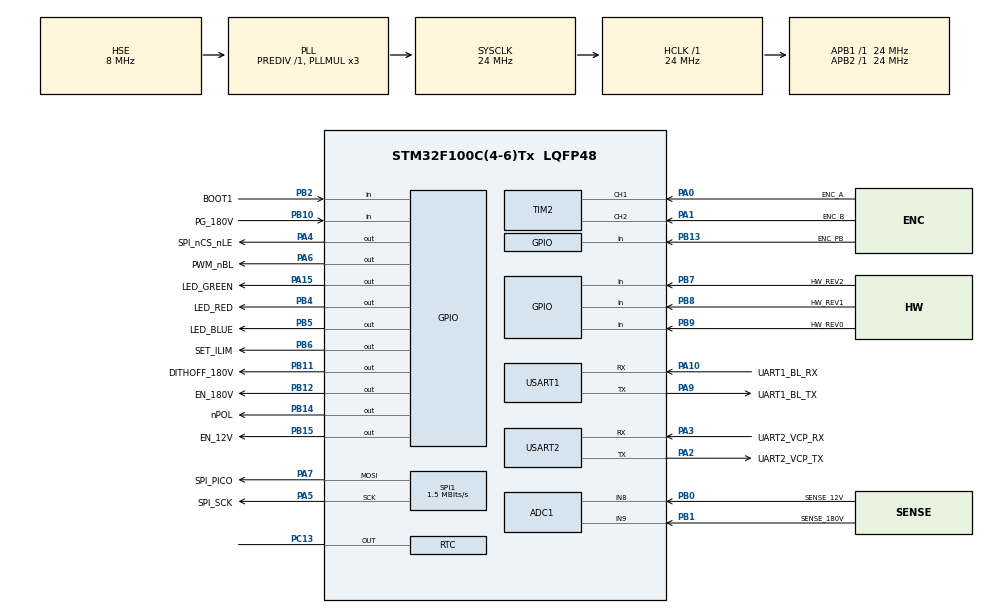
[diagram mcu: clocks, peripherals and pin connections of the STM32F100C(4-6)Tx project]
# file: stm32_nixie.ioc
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ADC1.Channel-4\#ChannelRegularConversion=ADC_CHANNEL_9
ADC1.NbrOfConversionFlag=1
ADC1.Rank-4\#ChannelRegularConversion=1
ADC1.SamplingTime-4\#ChannelRegularConversion=ADC_SAMPLETIME_1CYCLE_5
ADC1.master=1
Mcu.Family=STM32F1
Mcu.Name=STM32F100C(4-6)Tx
Mcu.Package=LQFP48
NVIC.PriorityGroup=NVIC_PRIORITYGROUP_4
NVIC.TIM2_IRQn=true\:0\:0\:false\:false\:true\:true\:true\:true
PA0-WKUP.GPIO_Label=ENC_A
PA0-WKUP.Signal=S_TIM2_CH1_ETR
PA1.GPIO_Label=ENC_B
PA1.Signal=S_TIM2_CH2
PA10.GPIO_Label=UART1_BL_RX
PA10.Mode=Asynchronous
PA10.Signal=USART1_RX
PA13.Mode=Serial_Wire
PA13.Signal=SYS_JTMS-SWDIO
PA14.Mode=Serial_Wire
PA14.Signal=SYS_JTCK-SWCLK
PA15.GPIO_Label=LED_GREEN
PA15.Signal=GPIO_Output
PA2.GPIO_Label=UART2_VCP_TX
PA2.Mode=Asynchronous
PA2.Signal=USART2_TX
PA3.GPIO_Label=UART2_VCP_RX
PA3.Mode=Asynchronous
PA3.Signal=USART2_RX
PA4.GPIO_Label=SPI_nCS_nLE
PA4.Signal=GPIO_Output
PA5.GPIO_Label=SPI_SCK
PA5.Mode=TX_Only_Simplex_Unidirect_Master
PA5.Signal=SPI1_SCK
PA6.GPIO_Label=PWM_nBL
PA6.Signal=GPIO_Output
PA7.GPIO_Label=SPI_PICO
PA7.Mode=TX_Only_Simplex_Unidirect_Master
PA7.Signal=SPI1_MOSI
PA9.GPIO_Label=UART1_BL_TX
PA9.Mode=Asynchronous
PA9.Signal=USART1_TX
PB0.GPIO_Label=SENSE_12V
PB0.Signal=ADCx_IN8
PB1.GPIO_Label=SENSE_180V
PB1.Signal=ADCx_IN9
PB10.GPIO_Label=PG_180V
PB10.Signal=GPIO_Input
PB11.GPIO_Label=DITHOFF_180V
PB11.Signal=GPIO_Output
PB12.GPIO_Label=EN_180V
PB12.Signal=GPIO_Output
PB13.GPIO_Label=ENC_PB
PB13.Signal=GPIO_Input
PB14.GPIO_Label=nPOL
PB14.Signal=GPIO_Output
PB15.GPIO_Label=EN_12V
PB15.Signal=GPIO_Output
PB2.GPIO_Label=BOOT1
PB2.Signal=GPIO_Input
PB3.Signal=SYS_JTDO-TRACESWO
PB4.GPIO_Label=LED_RED
PB4.Signal=GPIO_Output
PB5.GPIO_Label=LED_BLUE
PB5.Signal=GPIO_Output
PB6.GPIO_Label=SET_ILIM
PB6.Signal=GPIO_Output
PB7.GPIO_Label=HW_REV2
PB7.GPIO_PuPd=GPIO_PULLUP
PB7.Signal=GPIO_Input
PB8.GPIO_Label=HW_REV1
PB8.GPIO_PuPd=GPIO_PULLUP
PB8.Signal=GPIO_Input
PB9.GPIO_Label=HW_REV0
PB9.GPIO_PuPd=GPIO_PULLUP
PB9.Signal=GPIO_Input
PC13-TAMPER-RTC.Mode=RTC OUT
PC13-TAMPER-RTC.Signal=RTC_OUT
PC14-OSC32_IN.Mode=LSE-External-Oscillator
PC14-OSC32_IN.Signal=RCC_OSC32_IN
PC15-OSC32_OUT.Mode=LSE-External-Oscillator
PC15-OSC32_OUT.Signal=RCC_OSC32_OUT
PD0-OSC_IN.Mode=HSE-External-Oscillator
PD0-OSC_IN.Signal=RCC_OSC_IN
PD1-OSC_OUT.Mode=HSE-External-Oscillator
PD1-OSC_OUT.Signal=RCC_OSC_OUT
ProjectManager.HeapSize=0x200
ProjectManager.StackSize=0x400
ProjectManager.TargetToolchain=CMake
RCC.AHBFreq_Value=24000000
RCC.APB1Freq_Value=24000000
RCC.APB1TimFreq_Value=24000000
RCC.APB2Freq_Value=24000000
RCC.APB2TimFreq_Value=24000000
RCC.HCLKFreq_Value=24000000
RCC.PLLMUL=RCC_PLL_MUL3
RCC.PLLSource=RCC_PLLSOURCE_HSE
RCC.RTCClockSelection=RCC_RTCCLKSOURCE_LSE
RCC.SYSCLKFreq_VALUE=24000000
RCC.SYSCLKSource=RCC_SYSCLKSOURCE_PLLCLK
RTC.OutPut=RTC_OUTPUTSOURCE_CALIBCLOCK
SH.ADCx_IN8.0=ADC1_IN8,IN8
SH.ADCx_IN9.0=ADC1_IN9,IN9
SH.S_TIM2_CH1_ETR.0=TIM2_CH1,Encoder_Interface
SH.S_TIM2_CH2.0=TIM2_CH2,Encoder_Interface
SPI1.BaudRatePrescaler=SPI_BAUDRATEPRESCALER_16
SPI1.CLKPhase=SPI_PHASE_2EDGE
SPI1.CalculateBaudRate=1.5 MBits/s
SPI1.DataSize=SPI_DATASIZE_8BIT
SPI1.Direction=SPI_DIRECTION_2LINES
SPI1.Mode=SPI_MODE_MASTER
SPI1.VirtualType=VM_MASTER
TIM2.AutoReloadPreload=TIM_AUTORELOAD_PRELOAD_ENABLE
TIM2.EncoderMode=TIM_ENCODERMODE_TI12
USART1.Parity=PARITY_EVEN
USART1.VirtualMode=VM_ASYNC
USART2.VirtualMode=VM_ASYNC
VP_RTC_VS_RTC_Activate.Mode=RTC_Enabled
board=custom

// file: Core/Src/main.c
/* USER CODE BEGIN Header */
// clang-format off
/**
 ******************************************************************************
 * @file           : main.c
 * @brief          : Main program body
 ******************************************************************************
 * @attention
 *
 * Copyright (c) 2024 STMicroelectronics.
 * All rights reserved.
 *
 * This software is licensed under terms that can be found in the LICENSE file
 * in the root directory of this software component.
 * If no LICENSE file comes with this software, it is provided AS-IS.
 *
 ******************************************************************************
 */
/* USER CODE END Header */
#include "main.h"

#include "adc.h"
#include "gpio.h"
#include "rtc.h"
#include "spi.h"
#include "tim.h"
#include "usart.h"

/* USER CODE BEGIN Includes */
#include "main_app.hh"

/* USER CODE END Includes */

void SystemClock_Config(void);

int main(void) {

  /* MCU Configuration--------------------------------------------------------*/

  /* Reset of all peripherals, Initializes the Flash interface and the Systick.
   */
  HAL_Init();

  /* Configure the system clock */
  SystemClock_Config();

  /* Initialize all configured peripherals */
  MX_GPIO_Init();
  MX_RTC_Init();
  MX_SPI1_Init();
  MX_USART1_UART_Init();
  MX_USART2_UART_Init();
  MX_ADC1_Init();
  MX_TIM2_Init();

  /* Infinite loop */
  /* USER CODE BEGIN WHILE */

  main_app();  // Contains our super loop, so the while loop below will never be
               // executed

  /* USER CODE END WHILE */

}

void SystemClock_Config(void) {
  RCC_OscInitTypeDef RCC_OscInitStruct = {0};
  RCC_ClkInitTypeDef RCC_ClkInitStruct = {0};
  RCC_PeriphCLKInitTypeDef PeriphClkInit = {0};

  /** Initializes the RCC Oscillators according to the specified parameters
   * in the RCC_OscInitTypeDef structure.
   */
  RCC_OscInitStruct.OscillatorType =
      RCC_OSCILLATORTYPE_HSE | RCC_OSCILLATORTYPE_LSE;
  RCC_OscInitStruct.HSEState = RCC_HSE_ON;
  RCC_OscInitStruct.HSEPredivValue = RCC_HSE_PREDIV_DIV1;
  RCC_OscInitStruct.LSEState = RCC_LSE_ON;
  RCC_OscInitStruct.PLL.PLLState = RCC_PLL_ON;
  RCC_OscInitStruct.PLL.PLLSource = RCC_PLLSOURCE_HSE;
  RCC_OscInitStruct.PLL.PLLMUL = RCC_PLL_MUL3;
  if (HAL_RCC_OscConfig(&RCC_OscInitStruct) != HAL_OK) {
    Error_Handler();
  }

  /** Initializes the CPU, AHB and APB buses clocks
   */
  RCC_ClkInitStruct.ClockType = RCC_CLOCKTYPE_HCLK | RCC_CLOCKTYPE_SYSCLK |
                                RCC_CLOCKTYPE_PCLK1 | RCC_CLOCKTYPE_PCLK2;
  RCC_ClkInitStruct.SYSCLKSource = RCC_SYSCLKSOURCE_PLLCLK;
  RCC_ClkInitStruct.AHBCLKDivider = RCC_SYSCLK_DIV1;
  RCC_ClkInitStruct.APB1CLKDivider = RCC_HCLK_DIV1;
  RCC_ClkInitStruct.APB2CLKDivider = RCC_HCLK_DIV1;

  if (HAL_RCC_ClockConfig(&RCC_ClkInitStruct, FLASH_LATENCY_0) != HAL_OK) {
    Error_Handler();
  }
  PeriphClkInit.PeriphClockSelection = RCC_PERIPHCLK_RTC | RCC_PERIPHCLK_ADC;
  PeriphClkInit.RTCClockSelection = RCC_RTCCLKSOURCE_LSE;
  PeriphClkInit.AdcClockSelection = RCC_ADCPCLK2_DIV2;
  if (HAL_RCCEx_PeriphCLKConfig(&PeriphClkInit) != HAL_OK) {
    Error_Handler();
  }
}

void Error_Handler(void) {
  __disable_irq();
  while (1) {
  }
}

#ifdef USE_FULL_ASSERT
/**
 * @brief  Reports the name of the source file and the source line number
 *         where the assert_param error has occurred.
 * @param  file: pointer to the source file name
 * @param  line: assert_param error line source number
 * @retval None
 */
void assert_failed(uint8_t *file, uint32_t line) {
  /* USER CODE BEGIN 6 */
  /* User can add his own implementation to report the file name and line
     number, ex: printf("Wrong parameters value: file %s on line %d\r\n", file,
     line) */
  /* USER CODE END 6 */
}
#endif /* USE_FULL_ASSERT */
